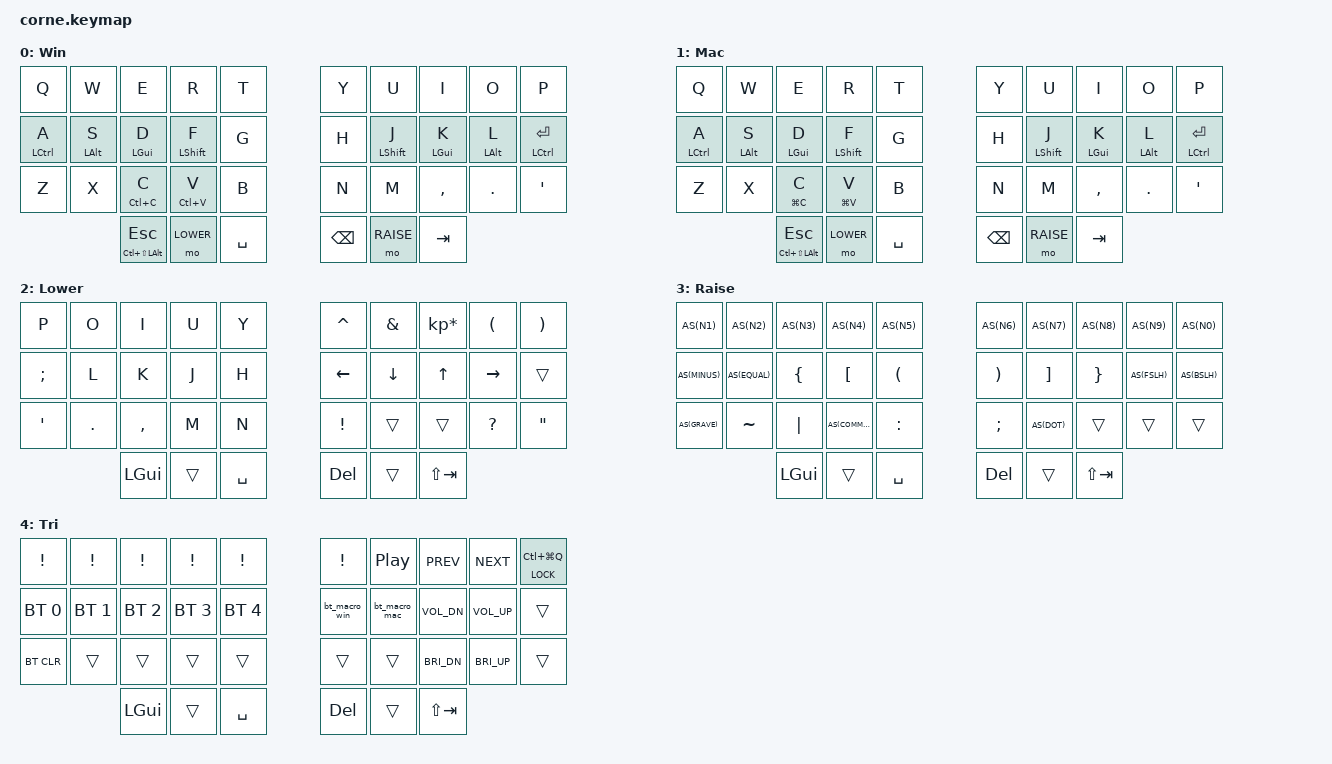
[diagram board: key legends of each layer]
/*
 * Copyright (c) 2020 The ZMK Contributors
 *
 * SPDX-License-Identifier: MIT
 */

#include <behaviors.dtsi>
#include <dt-bindings/zmk/keys.h>
#include <dt-bindings/zmk/bt.h>


#define AS(keycode) &as LS(keycode) keycode

// Revised homerow mods
#define HRML(k1,k2,k3,k4)  &ht LCTRL k1 &ht LALT k2 &ht LGUI k3 &ht LSHFT k4
#define HRMR(k1,k2,k3,k4)  &ht LSHFT k1 &ht LGUI k2 &ht LALT k3 &ht LCTRL k4


#define WHRML(k1,k2,k3,k4) &ht LGUI k1 &ht LALT k2 &ht LCTRL k3 &ht LSHFT k4
#define WHRMR(k1,k2,k3,k4) &ht LSHFT k1 &ht LCTRL k2 &ht LALT k3 &ht LGUI k4

#define WIN 0
#define MAC 1
#define LOWER 2
#define RAISE 3
#define TRI 4


/ {
    chosen {
      zmk,matrix_transform = &five_column_transform;
    };

    behaviors {
        as: auto_shift {
            compatible = "zmk,behavior-hold-tap";
            #binding-cells = <2>;
            tapping_term_ms = <185>;
            quick_tap_ms = <150>;
            require-prior-idle-ms = <125>;
            flavor = "balanced";
            bindings = <&kp>, <&kp>;
        };

         ht: hold_tap {
            label = "hold_tap";
            compatible = "zmk,behavior-hold-tap";
            #binding-cells = <2>;
            flavor = "balanced";
            tapping-term-ms = <185>;
            quick-tap-ms = <150>;
            require-prior-idle-ms = <125>;
            global-quick-tap;
            bindings = <&kp>, <&kp>;
        };

        sht: shift_hold_tap {
            label = "shift_hold_tap";
            compatible = "zmk,behavior-hold-tap";
            #binding-cells = <2>;
            flavor = "hold-preferred";
            tapping-term-ms = <170>;
            quick-tap-ms = <150>;
            require-prior-idle-ms = <125>;
            global-quick-tap;
            bindings = <&kp>, <&kp>;
        };

        conditional_layers {
            compatible = "zmk,conditional-layers";
            tri_layer {
                if-layers = <LOWER RAISE>;
                then-layer = <TRI>;
            };
        };

    };

    macros {
        bt_macro_win: bt_macro_win {
            label = "bt_macro_win";
            compatible = "zmk,behavior-macro";
            #binding-cells = <0>;
            wait-ms = <0>;
            tap-ms = <0>;
            bindings = <&to WIN>,  <&bt BT_SEL 0>;
        };
        bt_macro_mac: bt_macro_mac {
            label = "bt_macro_mac";
            compatible = "zmk,behavior-macro";
            #binding-cells = <0>;
            wait-ms = <0>;
            tap-ms = <0>;
            bindings = <&to MAC>,  <&bt BT_SEL 2>;
        };
    };
    
    keymap {
            compatible = "zmk,keymap";

                default_layer {
                        display-name = "Win";
                        bindings = <
   &kp Q &kp W &kp E &kp R &kp T     &kp Y   &kp U  &kp I     &kp O     &kp P
   &ht LCTRL A &ht LALT S &ht LGUI D &sht LSHFT F &kp G &kp H  &sht LSHFT J &ht LGUI K &ht LALT L &ht LCTRL RET
   &kp Z &kp X &ht LC(C) C &ht LC(V) V &kp B     &kp N   &kp M  &kp COMMA  &kp DOT  &kp SQT
        &sht LC(LS(LALT)) ESC &mo LOWER &kp SPACE     &kp BACKSPACE &mo RAISE  &kp TAB
                        >;
                };

                mac_layer {
                        display-name = "Mac";
                        bindings = <
   &kp Q &kp W &kp E &kp R &kp T     &kp Y   &kp U  &kp I     &kp O     &kp P
   &ht LCTRL A &ht LALT S &ht LGUI D &sht LSHFT F &kp G &kp H  &sht LSHFT J &ht LGUI K &ht LALT L &ht LCTRL RET
   &kp Z &kp X &ht LG(C) C &ht LG(V) V &kp B     &kp N   &kp M  &kp COMMA  &kp DOT  &kp SQT
        &sht LC(LS(LALT)) ESC &mo LOWER &kp SPACE     &kp BACKSPACE &mo RAISE &kp TAB
                        >;
                };

                lower_layer {
                        display-name = "Lower";
                        bindings = <
   &kp P &kp O &kp I &kp U &kp Y        &kp CARET &kp AMPS  &kp KP_MULTIPLY &kp LPAR  &kp RPAR
   &kp SEMI &kp L &kp K &kp J &kp H      &kp LEFT  &kp DOWN  &kp UP  &kp RIGHT &trans 
   &kp SQT &kp DOT  &kp COMMA  &kp M  &kp N                 &kp EXCL    &trans    &trans        &kp QMARK    &kp DQT 
                             &kp LGUI     &trans       &kp SPACE        &kp DEL   &trans   &kp LS(TAB)
                        >;
                };

                raise_layer {
// -----------------------------------------------------------------------------------------
// | 1! |  2@ |  3# |  4$ |  5% |     |  6^ |  7& |  8* |  9(  |  0)  |
// | -_ |  =+ |  {  |  [  |  (  |     |  )  |  ]  |  }  |  /?  |  \|  |
// | `~ |     |     |  ,< |  :  |     |  ;  |  .> | CTRL| META |      |
//            | GUI | ESC | SPC |     | ENT |     | TAB |
                        display-name = "Raise";
                        bindings = <

   AS(N1)    AS(N2)    AS(N3)    AS(N4)    AS(N5)        AS(N6)    AS(N7)    AS(N8)    AS(N9)   AS(N0)
   AS(MINUS) AS(EQUAL) &kp LBRC  &kp LBKT  &kp LPAR      &kp RPAR  &kp RBKT  &kp RBRC  AS(FSLH) AS(BSLH)
   AS(GRAVE) &kp TILDE  &kp PIPE    AS(COMMA) &kp COLON     &kp SEMI  AS(DOT)   &trans &trans &trans
                       &kp LGUI  &trans   &kp SPACE     &kp DEL   &trans    &kp LS(TAB)
                        >;
                };

                tri_layer {
                        display-name = "Tri";
                       bindings = <
   &kp EXCL     &kp EXCL  &kp EXCL     &kp EXCL     &kp EXCL        &kp EXCL &kp C_PP &kp C_PREV  &kp C_NEXT  &ht K_LOCK LC(LG(Q))
   &bt BT_SEL 0 &bt BT_SEL 1 &bt BT_SEL 2 &bt BT_SEL 3 &bt BT_SEL 4  &bt_macro_win  &bt_macro_mac &kp C_VOL_DN  &kp C_VOL_UP &trans 
   &bt BT_CLR   &trans       &trans       &trans       &trans        &trans &trans &kp C_BRI_DN   &kp C_BRI_UP    &trans 
                             &kp LGUI     &trans       &kp SPACE      &kp DEL   &trans    &kp LS(TAB)
                        >;
                };
        };
};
